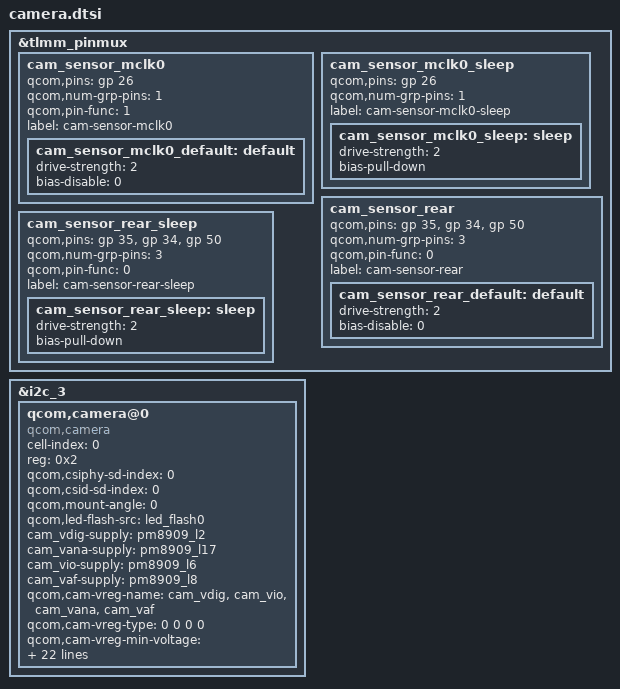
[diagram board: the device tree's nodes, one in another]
&tlmm_pinmux {
    cam_sensor_mclk0 {
        /* MCLK */
        qcom,pins = <&gp 26>;
        qcom,num-grp-pins = <1>;
        qcom,pin-func = <1>;
        label = "cam-sensor-mclk0";
            /* active state */
        cam_sensor_mclk0_default: default {
            drive-strength = <2>; /* 2 MA */
            bias-disable = <0>; /* No PULL */
        };
    };

    cam_sensor_mclk0_sleep {
        /* MCLK */
        qcom,pins = <&gp 26>;
        qcom,num-grp-pins = <1>;
        label = "cam-sensor-mclk0-sleep";
        /* suspend state */
        cam_sensor_mclk0_sleep: sleep {
            drive-strength = <2>; /* 2 MA */
            bias-pull-down; /* PULL DOWN */
        };
    };

	cam_sensor_rear {
		/* RESET, STANDBY */
		qcom,pins =  <&gp 35>, <&gp 34>, <&gp 50>;
		qcom,num-grp-pins = <3>;
		qcom,pin-func = <0>;
		label = "cam-sensor-rear";
		/* active state */
		cam_sensor_rear_default: default {
			drive-strength = <2>; /* 2 MA */
			bias-disable = <0>; /* No PULL */
		};
	};

	cam_sensor_rear_sleep {
		/* RESET, STANDBY */
		qcom,pins =  <&gp 35>, <&gp 34>, <&gp 50>;
		qcom,num-grp-pins = <3>;
		qcom,pin-func = <0>;
		label = "cam-sensor-rear-sleep";
		/*suspended state */
		cam_sensor_rear_sleep: sleep {
			drive-strength = <2>; /* 2 MA */
			bias-pull-down; /* PULL DOWN */
		};
	};
};

&i2c_3 {
	//Rear Camera
	qcom,camera@0 {
		cell-index = <0>;
		compatible = "qcom,camera";
		reg = <0x2>;
		qcom,csiphy-sd-index = <0>;
		qcom,csid-sd-index = <0>;
		qcom,mount-angle = <0>;
		//qcom,actuator-src = <&actuator0>;
		qcom,led-flash-src = <&led_flash0>;
		//qcom,eeprom-src = <&eeprom0>;
		cam_vdig-supply = <&pm8909_l2>;
		cam_vana-supply = <&pm8909_l17>;
		cam_vio-supply = <&pm8909_l6>;
		cam_vaf-supply = <&pm8909_l8>;
		qcom,cam-vreg-name = "cam_vdig", "cam_vio", "cam_vana",
							 "cam_vaf";
		qcom,cam-vreg-type = <0 0 0 0>;
		qcom,cam-vreg-min-voltage = <1200000 0 2800000 2850000>;
		qcom,cam-vreg-max-voltage = <1200000 0 2850000 2900000>;
		qcom,cam-vreg-op-mode = <200000 0 80000 100000>;
		pinctrl-names = "cam_default", "cam_suspend";
		pinctrl-0 = <&cam_sensor_mclk0_default &cam_sensor_rear_default>;
		pinctrl-1 = <&cam_sensor_mclk0_sleep &cam_sensor_rear_sleep>;
		gpios = <&msm_gpio 26 0>, //CAM0_CLK
			<&msm_gpio 35 0>,	//CAM0_RST
			<&msm_gpio 34 0>,	//CAM0_PWD
			<&msm_gpio 50 0>;	//Not Used		
		qcom,gpio-reset = <1>;
		qcom,gpio-standby = <2>;
		qcom,gpio-vdig = <3>;
		qcom,gpio-req-tbl-num = <0 1 2 3>;
		qcom,gpio-req-tbl-flags = <1 0 0 0>;
		qcom,gpio-req-tbl-label = "CAMIF_MCLK",
			"CAM_RESET1",
			"CAM_STANDBY",
			"CAM_VDIG";			
		qcom,sensor-position = <0>;
		qcom,sensor-mode = <0>;
		qcom,cci-master = <0>;
		status = "ok";
		clocks = <&clock_gcc clk_mclk0_clk_src>,
				<&clock_gcc clk_gcc_camss_mclk0_clk>;
		clock-names = "cam_src_clk", "cam_clk";
	};
};
